# PIC32CX1012BZ25048 register map
Vendor: Microchip Technology; Series: BZ25; File version: 0
CPU: CM4 r0p1, little endian, MPU, FPU, 3 interrupt priority bits
Registers are 32-bit, read-write, reset 0x0 unless marked. A register's access mark holds for its fields unless they carry their own. Offsets are from the block's base; [hi:lo] are bit positions; lines under a group give offsets from that group; {n}, {i} and the like mark numbered series.

## NVM — flash controller
Base 0x44000600; register names take the prefix NVM_
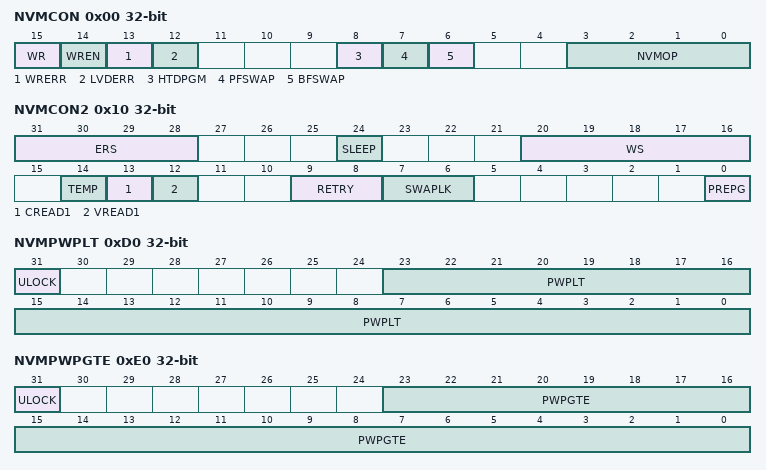
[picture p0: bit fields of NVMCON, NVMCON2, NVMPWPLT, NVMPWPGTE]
0x00 NVMCON
  [15] WR, [14] WREN, [13] WRERR, [12] LVDERR, [8] HTDPGM, [7] PFSWAP, [6] BFSWAP, [3:0] NVMOP
0x04 NVMCONCLR
0x08 NVMCONSET
0x0C NVMCONINV
0x10 NVMCON2
  [31:28] ERS, [24] SLEEP, [20:16] WS, [14] TEMP, [13] CREAD1, [12] VREAD1, [9:8] RETRY, [7:6] SWAPLK, [0] PREPG
0x14 NVMCON2CLR
0x18 NVMCON2SET
0x1C NVMCON2INV
0x20 NVMKEY
0x30 NVMADDR
{0x40+0x10*i} NVMDATA{i} (i=0..7)
0xC0 NVMSRCADDR
0xD0 NVMPWPLT
  [31] ULOCK, [23:0] PWPLT
0xD4 NVMPWPLTCLR
0xD8 NVMPWPLTSET
0xDC NVMPWPLTINV
0xE0 NVMPWPGTE
  [31] ULOCK, [23:0] PWPGTE
0xE4 NVMPWPGTECLR
0xE8 NVMPWPGTESET
0xEC NVMPWPGTEINV
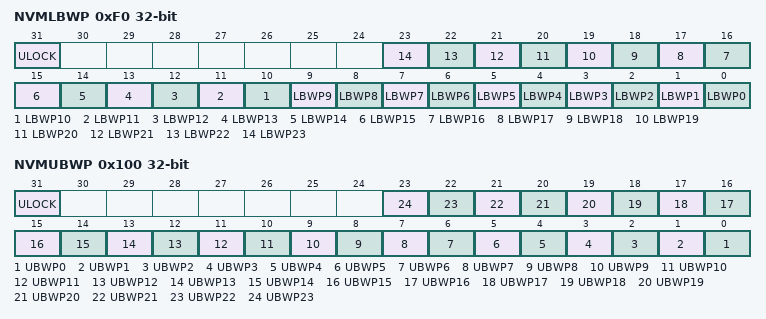
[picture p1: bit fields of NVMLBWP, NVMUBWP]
0xF0 NVMLBWP
  [31] ULOCK, [n] LBWP{n} (n=0..23)
0xF4 NVMLBWPCLR
0xF8 NVMLBWPSET
0xFC NVMLBWPINV
0x100 NVMUBWP
  [31] ULOCK, [n] UBWP{n} (n=0..23)
0x104 NVMUBWPCLR
0x108 NVMUBWPSET
0x10C NVMUBWPINV

## FREQM — Frequency Meter
Base 0x40000400; register names take the prefix FREQM_
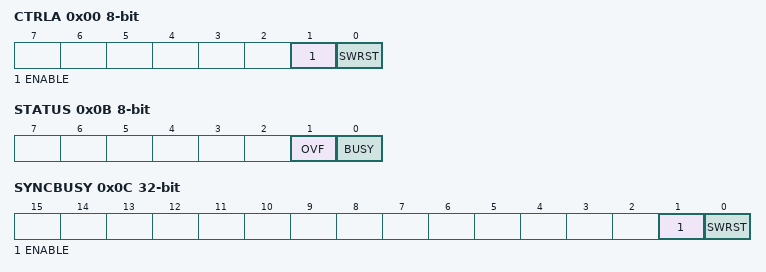
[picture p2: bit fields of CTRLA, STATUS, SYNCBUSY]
0x00 CTRLA 8-bit — Control A Register
  [1] ENABLE
  [0] SWRST — Software Reset
0x01 CTRLB 8-bit wo — Control B Register
  [0] START — Start Measurement
0x02 CFGA 16-bit — Config A register
  [7:0] REFNUM — Number of Reference Clock Cycles
0x08 INTENCLR 8-bit — Interrupt Enable Clear Register
  [0] DONE — Measurement Done Interrupt Enable
0x09 INTENSET 8-bit — Interrupt Enable Set Register
  [0] DONE — Measurement Done Interrupt Enable
0x0A INTFLAG 8-bit — Interrupt Flag Register
  [0] DONE — Measurement Done
0x0B STATUS 8-bit
  [1] OVF — Sticky Count Value Overflow
  [0] BUSY — FREQM Status
0x0C SYNCBUSY ro — Synchronization Busy Register
  [1] ENABLE
  [0] SWRST — Software Reset
0x10 VALUE ro — Count Value Register
  [23:0] VALUE — Measurement Value

## GPIOA — GPIO
Base 0x44002200; register names take the prefix GPIO_
Same registers: GPIOB 0x44002300
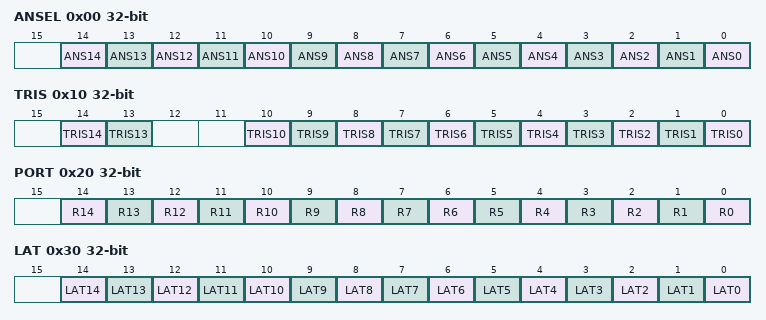
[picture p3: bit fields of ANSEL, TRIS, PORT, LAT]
0x00 ANSEL
  [n] ANS{n} (n=0..14)
0x04 ANSELCLR
0x08 ANSELSET
0x0C ANSELINV
0x10 TRIS
  [14] TRIS14, [13] TRIS13, [n] TRIS{n} (n=0..10)
0x14 TRISCLR
0x18 TRISSET
0x1C TRISINV
0x20 PORT
  [n] R{n} (n=0..14)
0x24 PORTCLR
0x28 PORTSET
0x2C PORTINV
0x30 LAT
  [n] LAT{n} (n=0..14)
0x34 LATCLR
0x38 LATSET
0x3C LATINV
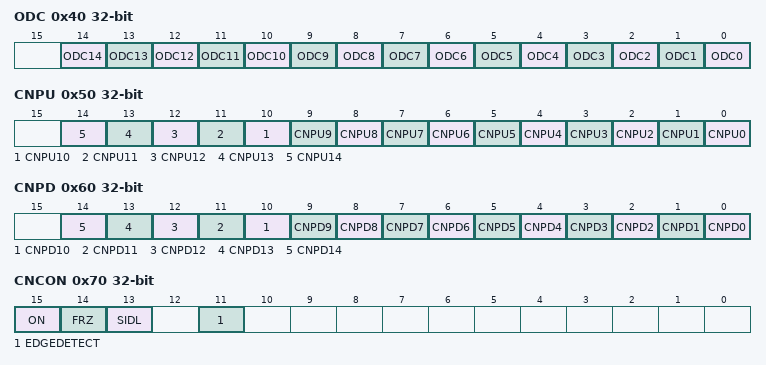
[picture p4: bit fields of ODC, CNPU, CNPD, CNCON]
0x40 ODC
  [n] ODC{n} (n=0..14)
0x44 ODCCLR
0x48 ODCSET
0x4C ODCINV
0x50 CNPU
  [n] CNPU{n} (n=0..14)
0x54 CNPUCLR
0x58 CNPUSET
0x5C CNPUINV
0x60 CNPD
  [n] CNPD{n} (n=0..14)
0x64 CNPDCLR
0x68 CNPDSET
0x6C CNPDINV
0x70 CNCON
  [15] ON, [14] FRZ, [13] SIDL, [11] EDGEDETECT
0x74 CNCONCLR
0x78 CNCONSET
0x7C CNCONINV
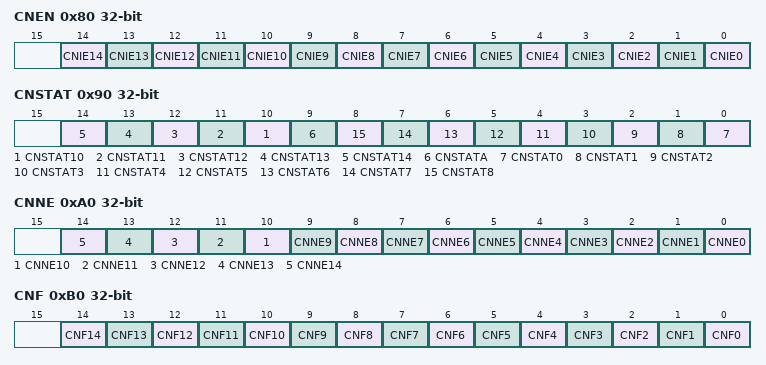
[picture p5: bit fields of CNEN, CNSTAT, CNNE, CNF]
0x80 CNEN
  [n] CNIE{n} (n=0..14)
0x84 CNENCLR
0x88 CNENSET
0x8C CNENINV
0x90 CNSTAT
  [n] CNSTAT{n} (n=10..14), [9] CNSTATA, [n] CNSTAT{n} (n=0..8)
0x94 CNSTATCLR
0x98 CNSTATSET
0x9C CNSTATINV
0xA0 CNNE
  [n] CNNE{n} (n=0..14)
0xA4 CNNECLR
0xA8 CNNESET
0xAC CNNEINV
0xB0 CNF
  [n] CNF{n} (n=0..14)
0xB4 CNFCLR
0xB8 CNFSET
0xBC CNFINV
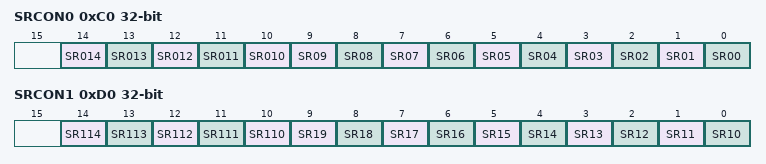
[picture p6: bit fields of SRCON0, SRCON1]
0xC0 SRCON0
  [n] SR{n:03} (n=10..14), [n] SR{n:02} (n=0..9)
0xC4 SRCON0CLR
0xC8 SRCON0SET
0xCC SRCON0INV
0xD0 SRCON1
  [n-100] SR{n} (n=110..114), [n-10] SR{n} (n=10..19)
0xD4 SRCON1CLR
0xD8 SRCON1SET
0xDC SRCON1INV

## HMATRIX — HSB Matrix
Base 0x42002400; register names take the prefix HMATRIXB_
{0x80+8i} PRS[{i}] (i=0..15) group
  0x00 PRAS — Priority A for Slave
  0x04 PRBS — Priority B for Slave

## ICM — Integrity Check Monitor
Base 0x42002C00; register names take the prefix ICM_
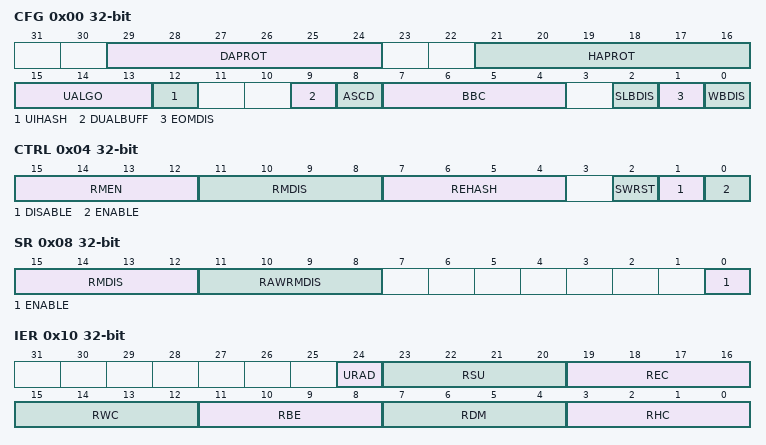
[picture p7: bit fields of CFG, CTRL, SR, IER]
0x00 CFG — Configuration
  [29:24] DAPROT — Region Descriptor Area Protection
  [21:16] HAPROT — Region Hash Area Protection
  [15:13] UALGO — User SHA Algorithm
    0=SHA1 (SHA1 Algorithm); 1=SHA256 (SHA256 Algorithm); 4=SHA224 (SHA224 Algorithm)
  [12] UIHASH — User Initial Hash Value
  [9] DUALBUFF — Dual Input Buffer
  [8] ASCD — Automatic Switch To Compare Digest
  [7:4] BBC — Bus Burden Control
  [2] SLBDIS — Secondary List Branching Disable
  [1] EOMDIS — End of Monitoring Disable
  [0] WBDIS — Write Back Disable
0x04 CTRL wo — Control
  [15:12] RMEN — Region Monitoring Enable
  [11:8] RMDIS — Region Monitoring Disable
  [7:4] REHASH — Recompute Internal Hash
  [2] SWRST — Software Reset
  [1] DISABLE — ICM Disable Register
  [0] ENABLE — ICM Enable
0x08 SR ro — Status
  [15:12] RMDIS — Region Monitoring Disabled Status
  [11:8] RAWRMDIS — RAW Region Monitoring Disabled Status
  [0] ENABLE — ICM Controller Enable Register
0x10 IER wo — Interrupt Enable
  [24] URAD — Undefined Register Access Detection Interrupt Enable
  [23:20] RSU — Region Status Updated Interrupt Disable
  [19:16] REC — Region End bit Condition Detected Interrupt Enable
  [15:12] RWC — Region Wrap Condition detected Interrupt Enable
  [11:8] RBE — Region Bus Error Interrupt Enable
  [7:4] RDM — Region Digest Mismatch Interrupt Enable
  [3:0] RHC — Region Hash Completed Interrupt Enable
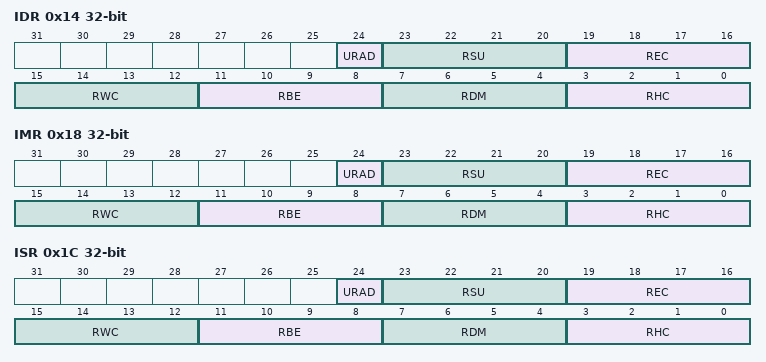
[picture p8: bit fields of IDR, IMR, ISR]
0x14 IDR wo — Interrupt Disable
  [24] URAD — Undefined Register Access Detection Interrupt Disable
  [23:20] RSU — Region Status Updated Interrupt Disable
  [19:16] REC — Region End bit Condition detected Interrupt Disable
  [15:12] RWC — Region Wrap Condition Detected Interrupt Disable
  [11:8] RBE — Region Bus Error Interrupt Disable
  [7:4] RDM — Region Digest Mismatch Interrupt Disable
  [3:0] RHC — Region Hash Completed Interrupt Disable
0x18 IMR ro — Interrupt Mask
  [24] URAD — Undefined Register Access Detection Interrupt Mask
  [23:20] RSU — Region Status Updated Interrupt Mask
  [19:16] REC — Region End bit Condition Detected Interrupt Mask
  [15:12] RWC — Region Wrap Condition Detected Interrupt Mask
  [11:8] RBE — Region Bus Error Interrupt Mask
  [7:4] RDM — Region Digest Mismatch Interrupt Mask
  [3:0] RHC — Region Hash Completed Interrupt Mask
0x1C ISR ro — Interrupt Status
  [24] URAD — Undefined Register Access Detection Status
  [23:20] RSU — Region Status Updated Detected
  [19:16] REC — Region End bit Condition Detected
  [15:12] RWC — Region Wrap Condition Detected
  [11:8] RBE — Region Bus Error
  [7:4] RDM — Region Digest Mismatch
  [3:0] RHC — Region Hash Completed
0x20 UASR ro — Undefined Access Status
  [2:0] URAT — Undefined Register Access Trace
    0=UNSPEC_STRUCT_MEMBER (Unspecified structure member set to one detected when the descriptor is loaded); 1=CFG_MODIFIED (CFG modified during active monitoring); 2=DSCR_MODIFIED (DSCR modified during active monitoring); 3=HASH_MODIFIED (HASH modified during active monitoring); 4=READ_ACCESS (Write-only register read access)
0x30 DSCR — Region Descriptor Area Start Address
  [31:6] DASA — Descriptor Area Start Address
0x34 HASH — Region Hash Area Start Address
  [31:7] HASA — Hash Area Start Address
{0x38+4i} UIHVAL[{i}] (i=0..7) wo — User Initial Hash Value n
  [31:0] VAL — Initial Hash Value

## Notices in the file
Copyright (c) 2017 Microchip Technology Inc.
SPDX-License-Identifier: Apache-2.0
Licensed under the Apache License, Version 2.0 (the "License");
you may not use this file except in compliance with the License.
You may obtain a copy of the License at
http://www.apache.org/licenses/LICENSE-2.0
Unless required by applicable law or agreed to in writing, software
distributed under the License is distributed on an "AS IS" BASIS,
WITHOUT WARRANTIES OR CONDITIONS OF ANY KIND, either express or implied.
See the License for the specific language governing permissions and
limitations under the License.
